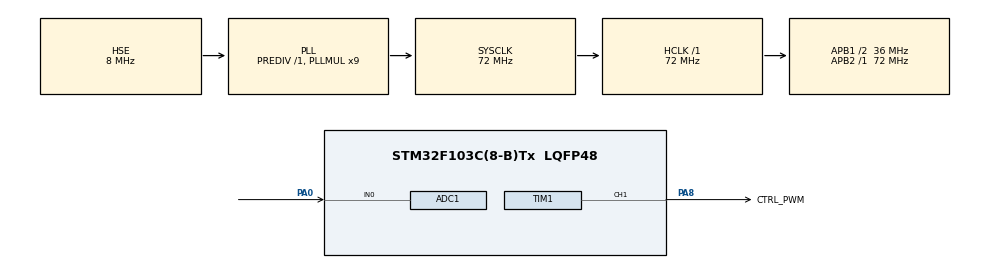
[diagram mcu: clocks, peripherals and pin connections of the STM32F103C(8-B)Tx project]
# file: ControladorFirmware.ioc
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ADC1.Channel-0\#ChannelRegularConversion=ADC_CHANNEL_0
ADC1.ExternalTrigConv=ADC_EXTERNALTRIGCONV_T1_CC1
ADC1.NbrOfConversionFlag=1
ADC1.Rank-0\#ChannelRegularConversion=1
ADC1.SamplingTime-0\#ChannelRegularConversion=ADC_SAMPLETIME_1CYCLE_5
ADC1.master=1
Mcu.Family=STM32F1
Mcu.Name=STM32F103C(8-B)Tx
Mcu.Package=LQFP48
NVIC.ADC1_2_IRQn=true\:0\:0\:false\:false\:true\:true\:true\:true
NVIC.PriorityGroup=NVIC_PRIORITYGROUP_4
PA0-WKUP.Signal=ADCx_IN0
PA13.Mode=Serial_Wire
PA13.Signal=SYS_JTMS-SWDIO
PA14.Mode=Serial_Wire
PA14.Signal=SYS_JTCK-SWCLK
PA8.GPIO_Label=CTRL_PWM
PA8.Signal=S_TIM1_CH1
PD0-OSC_IN.Mode=HSE-External-Oscillator
PD0-OSC_IN.Signal=RCC_OSC_IN
PD1-OSC_OUT.Mode=HSE-External-Oscillator
PD1-OSC_OUT.Signal=RCC_OSC_OUT
ProjectManager.HeapSize=0x200
ProjectManager.StackSize=0x400
ProjectManager.TargetToolchain=CMake
RCC.ADCPresc=RCC_ADCPCLK2_DIV6
RCC.AHBFreq_Value=72000000
RCC.APB1CLKDivider=RCC_HCLK_DIV2
RCC.APB1Freq_Value=36000000
RCC.APB1TimFreq_Value=72000000
RCC.APB2Freq_Value=72000000
RCC.APB2TimFreq_Value=72000000
RCC.HCLKFreq_Value=72000000
RCC.PLLMUL=RCC_PLL_MUL9
RCC.PLLSourceVirtual=RCC_PLLSOURCE_HSE
RCC.SYSCLKFreq_VALUE=72000000
RCC.SYSCLKSource=RCC_SYSCLKSOURCE_PLLCLK
RCC.USBFreq_Value=72000000
SH.ADCx_IN0.0=ADC1_IN0,IN0
SH.S_TIM1_CH1.0=TIM1_CH1,PWM Generation1 CH1
TIM1.Channel-PWM\ Generation1\ CH1=TIM_CHANNEL_1
TIM1.Period=1440-1
TIM1.TIM_MasterOutputTrigger=TIM_TRGO_UPDATE
VP_TIM1_VS_ClockSourceINT.Mode=Internal
board=custom

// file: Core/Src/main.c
/* USER CODE BEGIN Header */
/**
  ******************************************************************************
  * @file           : main.c
  * @brief          : Main program body
  ******************************************************************************
  * @attention
  *
  * Copyright (c) 2026 STMicroelectronics.
  * All rights reserved.
  *
  * This software is licensed under terms that can be found in the LICENSE file
  * in the root directory of this software component.
  * If no LICENSE file comes with this software, it is provided AS-IS.
  *
  ******************************************************************************
  */
/* USER CODE END Header */
#include "main.h"

/* USER CODE BEGIN PD */
#define VREF_INICIAL      25.0f
#define VREF_INCREMENTO   10.0f
#define TEMPO_DEGRAU_SEC  3.0f
#define TICKS_PARA_DEGRAU (uint32_t)(TEMPO_DEGRAU_SEC * 50000) // A 50kHz, 1 segundo = 50.000 interrupções
/* USER CODE END PD */

ADC_HandleTypeDef hadc1;

TIM_HandleTypeDef htim1;

/* USER CODE BEGIN PV */
  static float pastU = 0.0f;
  static float pastE = 0.0f;
  static float Vref = VREF_INICIAL;
  static uint32_t t_ticks = 0;

  // Variáveis para medição de performance
  volatile uint32_t ciclos_inicio = 0;
  volatile uint32_t ciclos_fim = 0;
  volatile uint32_t ciclos_atual = 0;
  volatile uint32_t ciclos_maximo = 0;

/* USER CODE END PV */

void SystemClock_Config(void);
static void MX_GPIO_Init(void);
static void MX_ADC1_Init(void);
static void MX_TIM1_Init(void);

/* USER CODE BEGIN 0 */
// Esta função é chamada automaticamente pelo hardware assim que o ADC termina de
// converter o sinal trigado pelo Timer 1. Custo de espera = 0 ciclos.
void HAL_ADCEx_InjectedConvCpltCallback(ADC_HandleTypeDef *hadc) {
  if (hadc->Instance == ADC1) {
    ciclos_inicio = DWT->CYCCNT; // <--- CAPTURA O CLOCK INICIAL

    /* 1. LEITURA IMEDIATA DO ADC */
    // Pega o valor já convertido do registrador de injeção (Rank 1)
    uint32_t adc_raw = HAL_ADCEx_InjectedGetValue(&hadc1, ADC_INJECTED_RANK_1);

    float IN = (float)adc_raw * 0.0122100122f;

    /* 2. GERAÇÃO DO DEGRAU DE TEMPO */
    t_ticks++;
    if (t_ticks >= TICKS_PARA_DEGRAU) {
      Vref = VREF_INICIAL + VREF_INCREMENTO;
    } else {
      Vref = VREF_INICIAL;
    }

    /* 3. CÁLCULO DO ERRO E LEI DE CONTROLE PI */
    float E = Vref - IN;

    float U = pastU + 0.000357719f * E + 0.000346881f * pastE;

    /* 4. SATURAÇÃO DO SINAL DE CONTROLE */
    if (U > 1.0f)
      U = 1.0f;
    else if (U < 0.0f)
      U = 0.0f;

    /* 5. ATUALIZAÇÃO DOS ESTADOS */
    pastE = E;
    pastU = U;

    /* 6. SAÍDA PARA O PWM EM HARDWARE */
    TIM1->CCR1 = (uint32_t)(U * 1440.0f);

    ciclos_fim = DWT->CYCCNT; // <--- CAPTURA O CLOCK FINAL
    ciclos_atual = ciclos_fim - ciclos_inicio;
    if (ciclos_atual > ciclos_maximo)  ciclos_maximo = ciclos_atual;
  }
}
/* USER CODE END 0 */

int main(void)
{

  /* MCU Configuration--------------------------------------------------------*/

  /* Reset of all peripherals, Initializes the Flash interface and the Systick. */
  HAL_Init();

  /* Configure the system clock */
  SystemClock_Config();

  /* Initialize all configured peripherals */
  MX_GPIO_Init();
  MX_ADC1_Init();
  MX_TIM1_Init();
  /* USER CODE BEGIN 2 */
  // Inicia o gerador de PWM
  HAL_TIM_PWM_Start(&htim1, TIM_CHANNEL_1);

  // Inicia o Timer base (para gerar os eventos TRGO)
  HAL_TIM_Base_Start(&htim1);

  // Inicia o ADC em modo injetado com interrupção.
  // A partir desta linha, o hardware faz o sincronismo sozinho.
  HAL_ADCEx_InjectedStart_IT(&hadc1);

  // --- Inicialização do DWT Cycle Counter ---
  CoreDebug->DEMCR |= CoreDebug_DEMCR_TRCENA_Msk; // Habilita o Trace
  DWT->CYCCNT = 0;                                // Zera o contador
  DWT->CTRL |= DWT_CTRL_CYCCNTENA_Msk;            // Habilita o contador

  /* USER CODE END 2 */

  /* Infinite loop */
  while (1)
  {

  }
}

void SystemClock_Config(void)
{
  RCC_OscInitTypeDef RCC_OscInitStruct = {0};
  RCC_ClkInitTypeDef RCC_ClkInitStruct = {0};
  RCC_PeriphCLKInitTypeDef PeriphClkInit = {0};

  /** Initializes the RCC Oscillators according to the specified parameters
  * in the RCC_OscInitTypeDef structure.
  */
  RCC_OscInitStruct.OscillatorType = RCC_OSCILLATORTYPE_HSE;
  RCC_OscInitStruct.HSEState = RCC_HSE_ON;
  RCC_OscInitStruct.HSEPredivValue = RCC_HSE_PREDIV_DIV1;
  RCC_OscInitStruct.HSIState = RCC_HSI_ON;
  RCC_OscInitStruct.PLL.PLLState = RCC_PLL_ON;
  RCC_OscInitStruct.PLL.PLLSource = RCC_PLLSOURCE_HSE;
  RCC_OscInitStruct.PLL.PLLMUL = RCC_PLL_MUL9;
  if (HAL_RCC_OscConfig(&RCC_OscInitStruct) != HAL_OK)
  {
    Error_Handler();
  }

  /** Initializes the CPU, AHB and APB buses clocks
  */
  RCC_ClkInitStruct.ClockType = RCC_CLOCKTYPE_HCLK|RCC_CLOCKTYPE_SYSCLK
                              |RCC_CLOCKTYPE_PCLK1|RCC_CLOCKTYPE_PCLK2;
  RCC_ClkInitStruct.SYSCLKSource = RCC_SYSCLKSOURCE_PLLCLK;
  RCC_ClkInitStruct.AHBCLKDivider = RCC_SYSCLK_DIV1;
  RCC_ClkInitStruct.APB1CLKDivider = RCC_HCLK_DIV2;
  RCC_ClkInitStruct.APB2CLKDivider = RCC_HCLK_DIV1;

  if (HAL_RCC_ClockConfig(&RCC_ClkInitStruct, FLASH_LATENCY_2) != HAL_OK)
  {
    Error_Handler();
  }
  PeriphClkInit.PeriphClockSelection = RCC_PERIPHCLK_ADC;
  PeriphClkInit.AdcClockSelection = RCC_ADCPCLK2_DIV6;
  if (HAL_RCCEx_PeriphCLKConfig(&PeriphClkInit) != HAL_OK)
  {
    Error_Handler();
  }
}

static void MX_ADC1_Init(void)
{

  ADC_ChannelConfTypeDef sConfig = {0};

  /** Common config
  */
  hadc1.Instance = ADC1;
  hadc1.Init.ScanConvMode = ADC_SCAN_DISABLE;
  hadc1.Init.ContinuousConvMode = DISABLE;
  hadc1.Init.DiscontinuousConvMode = DISABLE;
  hadc1.Init.ExternalTrigConv = ADC_EXTERNALTRIGCONV_T1_CC1;
  hadc1.Init.DataAlign = ADC_DATAALIGN_RIGHT;
  hadc1.Init.NbrOfConversion = 1;
  if (HAL_ADC_Init(&hadc1) != HAL_OK)
  {
    Error_Handler();
  }

  /** Configure Regular Channel
  */
  sConfig.Channel = ADC_CHANNEL_0;
  sConfig.Rank = ADC_REGULAR_RANK_1;
  sConfig.SamplingTime = ADC_SAMPLETIME_1CYCLE_5;
  if (HAL_ADC_ConfigChannel(&hadc1, &sConfig) != HAL_OK)
  {
    Error_Handler();
  }

}

static void MX_TIM1_Init(void)
{

  TIM_ClockConfigTypeDef sClockSourceConfig = {0};
  TIM_MasterConfigTypeDef sMasterConfig = {0};
  TIM_OC_InitTypeDef sConfigOC = {0};
  TIM_BreakDeadTimeConfigTypeDef sBreakDeadTimeConfig = {0};

  htim1.Instance = TIM1;
  htim1.Init.Prescaler = 0;
  htim1.Init.CounterMode = TIM_COUNTERMODE_UP;
  htim1.Init.Period = 1440-1;
  htim1.Init.ClockDivision = TIM_CLOCKDIVISION_DIV1;
  htim1.Init.RepetitionCounter = 0;
  htim1.Init.AutoReloadPreload = TIM_AUTORELOAD_PRELOAD_DISABLE;
  if (HAL_TIM_Base_Init(&htim1) != HAL_OK)
  {
    Error_Handler();
  }
  sClockSourceConfig.ClockSource = TIM_CLOCKSOURCE_INTERNAL;
  if (HAL_TIM_ConfigClockSource(&htim1, &sClockSourceConfig) != HAL_OK)
  {
    Error_Handler();
  }
  if (HAL_TIM_PWM_Init(&htim1) != HAL_OK)
  {
    Error_Handler();
  }
  sMasterConfig.MasterOutputTrigger = TIM_TRGO_UPDATE;
  sMasterConfig.MasterSlaveMode = TIM_MASTERSLAVEMODE_DISABLE;
  if (HAL_TIMEx_MasterConfigSynchronization(&htim1, &sMasterConfig) != HAL_OK)
  {
    Error_Handler();
  }
  sConfigOC.OCMode = TIM_OCMODE_PWM1;
  sConfigOC.Pulse = 0;
  sConfigOC.OCPolarity = TIM_OCPOLARITY_HIGH;
  sConfigOC.OCNPolarity = TIM_OCNPOLARITY_HIGH;
  sConfigOC.OCFastMode = TIM_OCFAST_DISABLE;
  sConfigOC.OCIdleState = TIM_OCIDLESTATE_RESET;
  sConfigOC.OCNIdleState = TIM_OCNIDLESTATE_RESET;
  if (HAL_TIM_PWM_ConfigChannel(&htim1, &sConfigOC, TIM_CHANNEL_1) != HAL_OK)
  {
    Error_Handler();
  }
  sBreakDeadTimeConfig.OffStateRunMode = TIM_OSSR_DISABLE;
  sBreakDeadTimeConfig.OffStateIDLEMode = TIM_OSSI_DISABLE;
  sBreakDeadTimeConfig.LockLevel = TIM_LOCKLEVEL_OFF;
  sBreakDeadTimeConfig.DeadTime = 0;
  sBreakDeadTimeConfig.BreakState = TIM_BREAK_DISABLE;
  sBreakDeadTimeConfig.BreakPolarity = TIM_BREAKPOLARITY_HIGH;
  sBreakDeadTimeConfig.AutomaticOutput = TIM_AUTOMATICOUTPUT_DISABLE;
  if (HAL_TIMEx_ConfigBreakDeadTime(&htim1, &sBreakDeadTimeConfig) != HAL_OK)
  {
    Error_Handler();
  }
  HAL_TIM_MspPostInit(&htim1);

}

static void MX_GPIO_Init(void)
{

  /* GPIO Ports Clock Enable */
  __HAL_RCC_GPIOD_CLK_ENABLE();
  __HAL_RCC_GPIOA_CLK_ENABLE();

}

void Error_Handler(void)
{
  __disable_irq();
  while (1)
  {
  }
}
